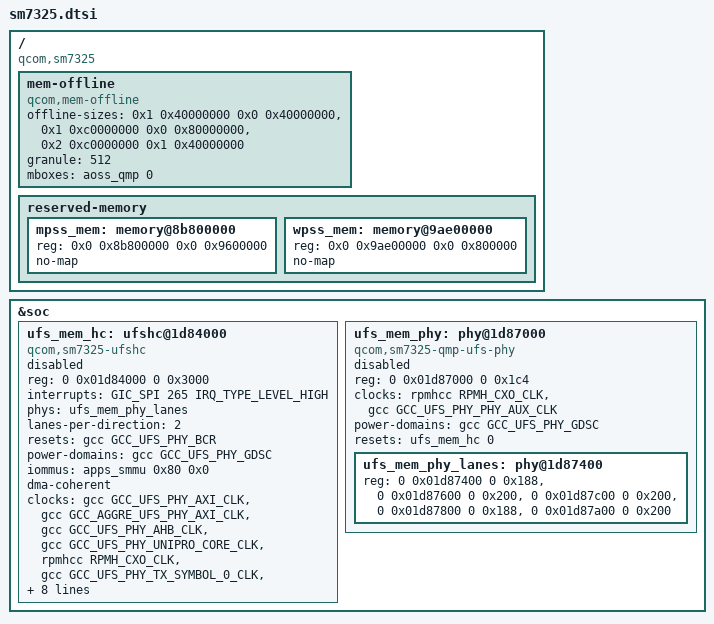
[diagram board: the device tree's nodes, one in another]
// SPDX-License-Identifier: BSD-3-Clause
/*
 * Copyright (c) 2021, The Linux Foundation. All rights reserved.
 * Copyright (c) 2026, Jiro <ktgithub28@gmail.com>
 *
 * Qualcomm SM7325 (Yupik) SoC device tree
 */

#include "sc7280.dtsi"

/ {
	compatible = "qcom,sm7325", "qcom,sc7280";

	/*
	 * Samsung SBOOT / ABL Bootloader constraint:
	 * mem-offline MUST NOT be deleted or moved. Samsung ABL parses this node
	 * and mailbox to negotiate RAM partitions with AOP. If deleted, DTBO
	 * phandles shift, triggering an EDTBO check fail and forcing Odin Download Mode.
	 */
	mem-offline {
		compatible = "qcom,mem-offline";
		offline-sizes = <0x1 0x40000000 0x0 0x40000000>,
				<0x1 0xc0000000 0x0 0x80000000>,
				<0x2 0xc0000000 0x1 0x40000000>;
		granule = <512>;
		mboxes = <&aoss_qmp 0>;
	};

	reserved-memory {
		#address-cells = <2>;
		#size-cells = <2>;
		ranges;

		mpss_mem: memory@8b800000 {
			reg = <0x0 0x8b800000 0x0 0x9600000>;
			no-map;
		};

		wpss_mem: memory@9ae00000 {
			reg = <0x0 0x9ae00000 0x0 0x800000>;
			no-map;
		};
	};
};

&soc {
	ufs_mem_hc: ufshc@1d84000 {
		compatible = "qcom,sm7325-ufshc", "qcom,ufshc", "jedec,ufs-2.0";
		reg = <0 0x01d84000 0 0x3000>;
		interrupts = <GIC_SPI 265 IRQ_TYPE_LEVEL_HIGH>;
		phys = <&ufs_mem_phy_lanes>;
		phy-names = "ufsphy";
		lanes-per-direction = <2>;
		#reset-cells = <1>;
		resets = <&gcc GCC_UFS_PHY_BCR>;
		reset-names = "rst";

		power-domains = <&gcc GCC_UFS_PHY_GDSC>;

		iommus = <&apps_smmu 0x80 0x0>;
		dma-coherent;

		clock-names =
			"core_clk",
			"bus_aggr_clk",
			"iface_clk",
			"core_clk_unipro",
			"ref_clk",
			"tx_lane0_sync_clk",
			"rx_lane0_sync_clk",
			"rx_lane1_sync_clk";
		clocks =
			<&gcc GCC_UFS_PHY_AXI_CLK>,
			<&gcc GCC_AGGRE_UFS_PHY_AXI_CLK>,
			<&gcc GCC_UFS_PHY_AHB_CLK>,
			<&gcc GCC_UFS_PHY_UNIPRO_CORE_CLK>,
			<&rpmhcc RPMH_CXO_CLK>,
			<&gcc GCC_UFS_PHY_TX_SYMBOL_0_CLK>,
			<&gcc GCC_UFS_PHY_RX_SYMBOL_0_CLK>,
			<&gcc GCC_UFS_PHY_RX_SYMBOL_1_CLK>;
		freq-table-hz =
			<75000000 300000000>,
			<0 0>,
			<0 0>,
			<75000000 300000000>,
			<0 0>,
			<0 0>,
			<0 0>,
			<0 0>;

		interconnects = <&aggre1_noc MASTER_UFS_MEM 0 &mc_virt SLAVE_EBI1 0>,
				<&gem_noc MASTER_APPSS_PROC 0 &cnoc2 SLAVE_UFS_MEM_CFG 0>;
		interconnect-names = "ufs-ddr", "cpu-ufs";

		status = "disabled";
	};

	ufs_mem_phy: phy@1d87000 {
		compatible = "qcom,sm7325-qmp-ufs-phy", "qcom,sm8350-qmp-ufs-phy";
		reg = <0 0x01d87000 0 0x1c4>;
		#address-cells = <2>;
		#size-cells = <2>;
		ranges;
		clock-names = "ref",
			      "ref_aux";
		clocks = <&rpmhcc RPMH_CXO_CLK>,
			 <&gcc GCC_UFS_PHY_PHY_AUX_CLK>;

		power-domains = <&gcc GCC_UFS_PHY_GDSC>;

		resets = <&ufs_mem_hc 0>;
		reset-names = "ufsphy";
		status = "disabled";

		ufs_mem_phy_lanes: phy@1d87400 {
			reg = <0 0x01d87400 0 0x188>,
			      <0 0x01d87600 0 0x200>,
			      <0 0x01d87c00 0 0x200>,
			      <0 0x01d87800 0 0x188>,
			      <0 0x01d87a00 0 0x200>;
			#clock-cells = <1>;
			#phy-cells = <0>;
		};
	};
};
